# STM32U5G9 register map
File version: 1.3
CPU: CM33 r0p1, little endian, MPU, FPU, 4 interrupt priority bits
Registers are 32-bit, read-write, reset 0x0 unless marked. A register's access mark holds for its fields unless they carry their own. Offsets are from the block's base; [hi:lo] are bit positions; {n}, {i} and the like mark numbered series.

## ADF1
Base 0x46024000
Same registers: SEC_ADF1 0x56024000
0x00 ADF_GCR — ADF Global Control Register
  [0] TRGO — Trigger output control Set by software and reset by
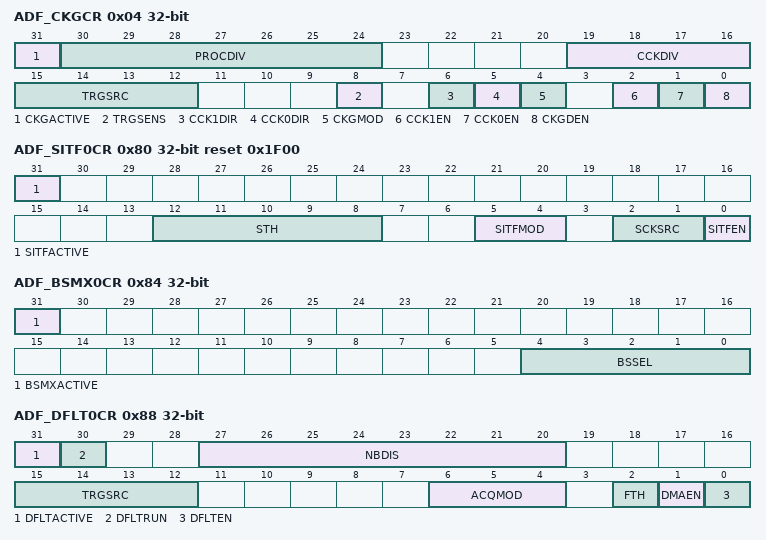
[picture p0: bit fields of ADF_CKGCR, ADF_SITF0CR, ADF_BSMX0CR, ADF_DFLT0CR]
0x04 ADF_CKGCR — ADF clock generator control register
  [31] CKGACTIVE — Clock generator active flag
  [30:24] PROCDIV — Divider to control the serial interface clock
  [19:16] CCKDIV — Divider to control the ADF_CCK clock
  [15:12] TRGSRC — Digital filter trigger signal selection
  [8] TRGSENS — CKGEN trigger sensitivity selection
  [6] CCK1DIR — ADF_CCK1 direction
  [5] CCK0DIR — ADF_CCK0 direction
  [4] CKGMOD — Clock generator mode
  [2] CCK1EN — ADF_CCK1 clock enable
  [1] CCK0EN — ADF_CCK0 clock enable
  [0] CKGDEN — CKGEN dividers enable
0x80 ADF_SITF0CR reset 0x1F00 — ADF serial interface control register 0
  [31] SITFACTIVE, [12:8] STH, [5:4] SITFMOD, [2:1] SCKSRC, [0] SITFEN
0x84 ADF_BSMX0CR — ADF bitstream matrix control register 0
  [31] BSMXACTIVE — BSMX active flag
  [4:0] BSSEL — Bitstream selection
0x88 ADF_DFLT0CR — ADF digital filter control register 0
  [31] DFLTACTIVE — DFLT0 active flag
  [30] DFLTRUN — DFLT0 run status flag
  [27:20] NBDIS — Number of samples to be discarded
  [15:12] TRGSRC — DFLT0 trigger signal selection
  [6:4] ACQMOD — DFLT0 trigger mode
  [2] FTH — RXFIFO threshold selection
  [1] DMAEN — DMA requests enable
  [0] DFLTEN — DFLT0 enable
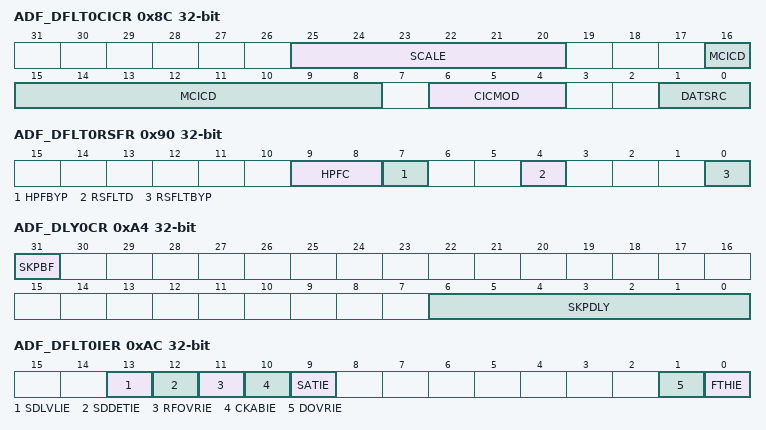
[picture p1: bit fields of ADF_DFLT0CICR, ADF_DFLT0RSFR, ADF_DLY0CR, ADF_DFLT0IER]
0x8C ADF_DFLT0CICR — ADF digital filer configuration register 0
  [25:20] SCALE — Scaling factor selection
  [16:8] MCICD — CIC decimation ratio selection
  [6:4] CICMOD — Select the CIC order
  [1:0] DATSRC — Source data for the digital filter
0x90 ADF_DFLT0RSFR — ADF reshape filter configuration register 0
  [9:8] HPFC — High-pass filter cut-off frequency
  [7] HPFBYP — High-pass filter bypass
  [4] RSFLTD — Reshaper filter decimation ratio
  [0] RSFLTBYP — Reshaper filter bypass
0xA4 ADF_DLY0CR — ADF delay control register 0
  [31] SKPBF — Skip busy flag
  [6:0] SKPDLY — Delay to apply to a bitstream
0xAC ADF_DFLT0IER — ADF DFLT0 interrupt enable register
  [13] SDLVLIE — SAD sound-level value ready enable
  [12] SDDETIE — Sound activity detection interrupt enable
  [11] RFOVRIE — Reshape filter overrun interrupt enable
  [10] CKABIE — Clock absence detection interrupt enable
  [9] SATIE — Saturation detection interrupt enable
  [1] DOVRIE — Data overflow interrupt enable
  [0] FTHIE — RXFIFO threshold interrupt enable
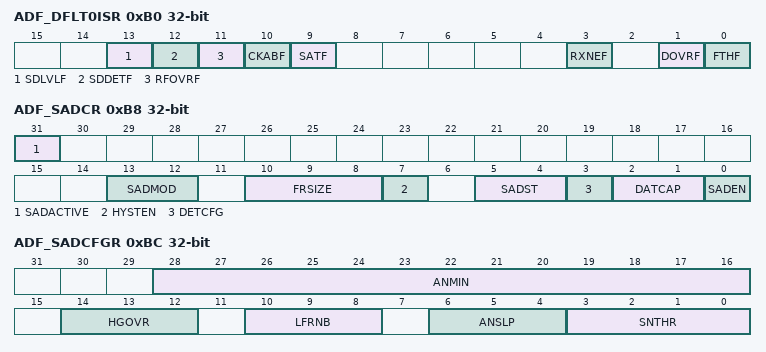
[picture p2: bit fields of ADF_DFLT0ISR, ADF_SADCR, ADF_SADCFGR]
0xB0 ADF_DFLT0ISR access per field — ADF DFLT0 interrupt status register 0
  [13] SDLVLF rw — Sound level value ready flag
  [12] SDDETF rw — Sound activity detection flag
  [11] RFOVRF rw — Reshape filter overrun detection flag
  [10] CKABF rw — Clock absence detection flag
  [9] SATF rw — Saturation detection flag
  [3] RXNEF ro — RXFIFO not empty flag
  [1] DOVRF rw — Data overflow flag
  [0] FTHF ro — RXFIFO threshold flag
0xB8 ADF_SADCR access per field — ADF SAD control register
  [31] SADACTIVE ro — SAD Active flag
  [13:12] SADMOD rw — SAD working mode
  [10:8] FRSIZE rw — Frame size
  [7] HYSTEN rw — Hysteresis enable
  [5:4] SADST ro — SAD state
  [3] DETCFG rw — Sound trigger event configuration
  [2:1] DATCAP rw — Data capture mode
  [0] SADEN rw — Sound activity detector enable
0xBC ADF_SADCFGR — ADF SAD configuration register
  [28:16] ANMIN
  [14:12] HGOVR — Hangover time window
  [10:8] LFRNB
  [6:4] ANSLP
  [3:0] SNTHR
0xC0 ADF_SADSDLVR ro — ADF SAD sound level register
  [14:0] SDLVL
0xC4 ADF_SADANLVR ro — ADF SAD ambient noise level register
  [14:0] ANLVL
0xF0 ADF_DFLT0DR ro — ADF digital filter data register 0
  [31:8] DR

## AES — Advanced encryption standard hardware accelerator
Base 0x420C0000
Same registers: SEC_AES 0x520C0000
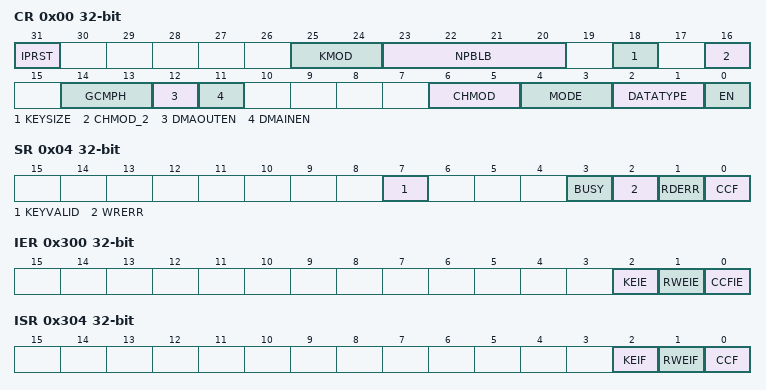
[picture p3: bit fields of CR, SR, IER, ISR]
0x00 CR — control register
  [31] IPRST
  [25:24] KMOD
  [23:20] NPBLB
  [18] KEYSIZE
  [16] CHMOD_2
  [14:13] GCMPH
  [12] DMAOUTEN — Enable DMA management of data output phase
  [11] DMAINEN — Enable DMA management of data input phase
  [6:5] CHMOD — AES chaining mode
  [4:3] MODE — AES operating mode
  [2:1] DATATYPE — Data type selection (for data in and data out to/from the cryptographic block)
  [0] EN — AES enable
0x04 SR ro — status register
  [7] KEYVALID — Key Valid flag
  [3] BUSY
  [2] WRERR — Write error flag
  [1] RDERR — Read error flag
  [0] CCF — Computation complete flag
0x08 DINR wo — data input register
  [31:0] DIN — Input data word
0x0C DOUTR ro — data output register
  [31:0] DOUT — Output data word
0x10 KEYR0 wo — key register 0
  [31:0] KEY — Cryptographic key, bits [31:0]
0x14 KEYR1 wo — key register 1
  [31:0] KEY — Cryptographic key, bits [63:32]
0x18 KEYR2 wo — key register 2
  [31:0] KEYR — Cryptographic key, bits [95:64]
0x1C KEYR3 wo — key register 3
  [31:0] AES_KEYR3 — Cryptographic key, bits [127:96]
{0x20+4i} IVR{i} (i=0..3) — initialization vector register {i}
  [31:0] IVI — Initialization vector input, bits [{32i+31}:{32i}]
{0x20+4i} KEYR{i} wo (i=4..7) — key register {i}
  [31:0] KEY — Cryptographic key, bits [{32i+31}:{32i}]
{0x40+4i} SUSP{i}R wo (i=0..7) — suspend registers
  [31:0] SUSP{i} — AES suspend
0x300 IER — interrupt enable register
  [2] KEIE — Key error interrupt flag
  [1] RWEIE — Read or write error interrupt flag
  [0] CCFIE — Computation complete flag
0x304 ISR ro — interrupt status register
  [2] KEIF — Key error interrupt flag
  [1] RWEIF — Read or write error interrupt flag
  [0] CCF — Computation complete flag
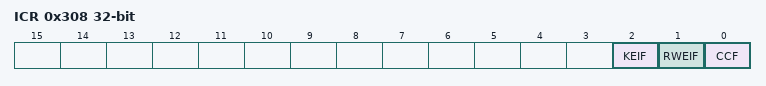
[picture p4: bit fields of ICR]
0x308 ICR wo — interrupt clear register
  [2] KEIF — Key error interrupt flag clear
  [1] RWEIF — Read or write error interrupt flag clear
  [0] CCF — Computation complete flag clear

## SAES — Secure AES coprocessor
Base 0x420C0C00
Same registers: SEC_SAES 0x520C0C00
Registers as AES (with AES read as SAES), without SUSP{n}R (n=0..7); these are added or differ:
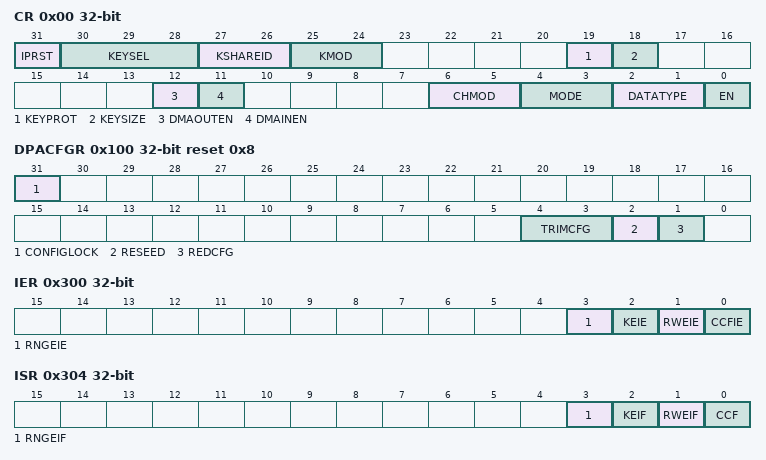
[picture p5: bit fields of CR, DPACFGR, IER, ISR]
0x00 CR — control register
  [31] IPRST
  [30:28] KEYSEL
  [27:26] KSHAREID
  [25:24] KMOD
  [19] KEYPROT
  [18] KEYSIZE
  [12] DMAOUTEN
  [11] DMAINEN
  [6:5] CHMOD
  [4:3] MODE
  [2:1] DATATYPE
  [0] EN — SAES enable
0x100 DPACFGR access per field reset 0x8 — configuration register
  [31] CONFIGLOCK ro, [4:3] TRIMCFG rw, [2] RESEED rw, [1] REDCFG rw
0x300 IER — interrupt enable register
  [3] RNGEIE
  [2] KEIE — Key error interrupt enable
  [1] RWEIE — Read or write error interrupt enable
  [0] CCFIE — Computation complete flag interrupt enable
0x304 ISR ro — interrupt status register
  [3] RNGEIF
  [2] KEIF — Key error interrupt flag
  [1] RWEIF — Read or write error interrupt flag
  [0] CCF — Computation complete flag
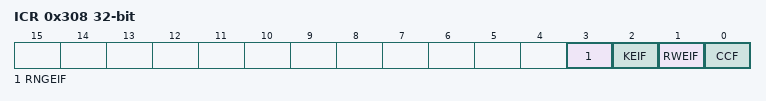
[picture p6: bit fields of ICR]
0x308 ICR wo — interrupt clear register
  [3] RNGEIF
  [2] KEIF — Key error interrupt flag clear
  [1] RWEIF — Read or write error interrupt flag clear
  [0] CCF — Computation complete flag clear

## Notices in the file
Copyright (c) 2026 STMicroelectronics.
SPDX-License-Identifier: Apache-2.0
Licensed under the Apache License, Version 2.0 (the "License");
you may not use this file except in compliance with the License.
You may obtain a copy of the License at
http://www.apache.org/licenses/LICENSE-2.0
Unless required by applicable law or agreed to in writing, software
distributed under the License is distributed on an "AS IS" BASIS,
WITHOUT WARRANTIES OR CONDITIONS OF ANY KIND, either express or implied.
See the License for the specific language governing permissions and
limitations under the License.
